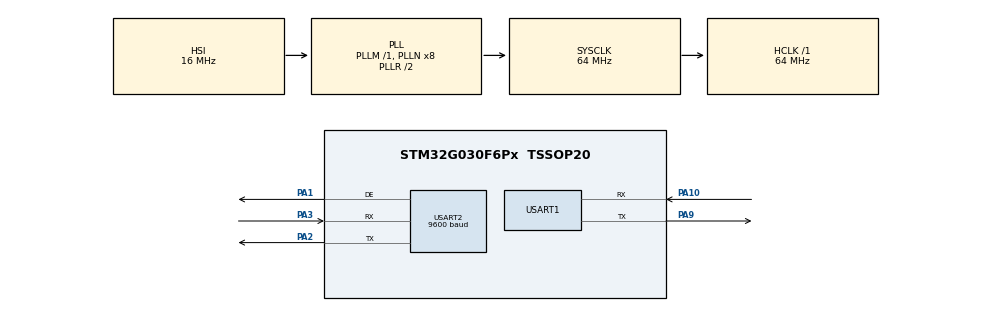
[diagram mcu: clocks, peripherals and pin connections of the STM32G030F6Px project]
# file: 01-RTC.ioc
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Mcu.Family=STM32G0
Mcu.Name=STM32G030F6Px
Mcu.Package=TSSOP20
NVIC.USART2_IRQn=true\:0\:0\:false\:false\:true\:true\:true\:true
PA1.Mode=Hardware Flow Control (RS485)
PA1.Signal=USART2_DE
PA10\ [PA12].Mode=Asynchronous
PA10\ [PA12].Signal=USART1_RX
PA13.Mode=Serial_Wire
PA13.Signal=SYS_SWDIO
PA14-BOOT0.Mode=Serial_Wire
PA14-BOOT0.Signal=SYS_SWCLK
PA14-BOOT0__PA15.StandardMode=true
PA2.Mode=Asynchronous
PA2.Signal=USART2_TX
PA3.Mode=Asynchronous
PA3.Signal=USART2_RX
PA9\ [PA11].Mode=Asynchronous
PA9\ [PA11].Signal=USART1_TX
PB0__PB1__PB2__PA8.StandardMode=true
PB3__PB4__PB5__PB6.StandardMode=true
PB7__PB8.StandardMode=true
PC14-OSC32_IN\ (PC14).Mode=LSE-External-Oscillator
PC14-OSC32_IN\ (PC14).Signal=RCC_OSC32_IN
PC14-OSC32_IN\ (PC14)__PB9.StandardMode=true
PC15-OSC32_OUT\ (PC15).Mode=LSE-External-Oscillator
PC15-OSC32_OUT\ (PC15).Signal=RCC_OSC32_OUT
ProjectManager.HeapSize=0x200
ProjectManager.StackSize=0x400
ProjectManager.TargetToolchain=STM32CubeIDE
RCC.ADCFreq_Value=64000000
RCC.AHBFreq_Value=64000000
RCC.CortexFreq_Value=64000000
RCC.EXTERNAL_CLOCK_VALUE=12288000
RCC.HCLKFreq_Value=64000000
RCC.HSE_VALUE=8000000
RCC.HSI_VALUE=16000000
RCC.RTCClockSelection=RCC_RTCCLKSOURCE_LSE
RCC.SYSCLKFreq_VALUE=64000000
RCC.SYSCLKSource=RCC_SYSCLKSOURCE_PLLCLK
RCC.VCOOutputFreq_Value=128000000
RTC.Year=23
USART1.VirtualMode-Asynchronous=VM_ASYNC
USART2.BaudRate=9600
USART2.VirtualMode-Asynchronous=VM_ASYNC
USART2.VirtualMode-Hardware\ Flow\ Control\ (RS485)=VM_ASYNC
VP_RTC_VS_RTC_Activate.Mode=RTC_Enabled
VP_RTC_VS_RTC_Calendar.Mode=RTC_Calendar
VP_SYS_VS_PINREMAP.Mode=PINREMAP
VP_SYS_VS_PINREMAP_10_12.Mode=PINREMAP_10_12
board=custom

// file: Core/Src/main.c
/* USER CODE BEGIN Header */
/**
  ******************************************************************************
  * @file           : main.c
  * @brief          : Main program body
  ******************************************************************************
  * @attention
  *
  * Copyright (c) 2026 STMicroelectronics.
  * All rights reserved.
  *
  * This software is licensed under terms that can be found in the LICENSE file
  * in the root directory of this software component.
  * If no LICENSE file comes with this software, it is provided AS-IS.
  *
  ******************************************************************************
  */
/* USER CODE END Header */
#include "main.h"
#include "rtc.h"
#include "usart.h"
#include "gpio.h"

/* USER CODE BEGIN Includes */
#include "modbus_slave.h"
/* USER CODE END Includes */

void SystemClock_Config(void);

int main(void)
{

  /* MCU Configuration--------------------------------------------------------*/

  /* Reset of all peripherals, Initializes the Flash interface and the Systick. */
  HAL_Init();

  /* Configure the system clock */
  SystemClock_Config();

  /* Initialize all configured peripherals */
  MX_GPIO_Init();
  MX_RTC_Init();
  MX_USART1_UART_Init();
  MX_USART2_UART_Init();
  /* USER CODE BEGIN 2 */
#ifndef LOOP_TEST_
  Modbus_Init();
#else
  // Optionally disable Modbus RX interrupt so it doesn't interfere
  __HAL_UART_DISABLE_IT(&huart2, UART_IT_RXNE);
#endif
  /* USER CODE END 2 */

  /* Infinite loop */
  while (1)
  {

    /* USER CODE BEGIN 3 */
#ifdef LOOP_TEST_
    RS485_LoopTest();
#else
    Modbus_Process();
#endif
  }
  /* USER CODE END 3 */
}

void SystemClock_Config(void)
{
  RCC_OscInitTypeDef RCC_OscInitStruct = {0};
  RCC_ClkInitTypeDef RCC_ClkInitStruct = {0};

  /** Configure the main internal regulator output voltage
  */
  HAL_PWREx_ControlVoltageScaling(PWR_REGULATOR_VOLTAGE_SCALE1);

  /** Configure LSE Drive Capability
  */
  HAL_PWR_EnableBkUpAccess();
  __HAL_RCC_LSEDRIVE_CONFIG(RCC_LSEDRIVE_LOW);

  /** Initializes the RCC Oscillators according to the specified parameters
  * in the RCC_OscInitTypeDef structure.
  */
  RCC_OscInitStruct.OscillatorType = RCC_OSCILLATORTYPE_HSI|RCC_OSCILLATORTYPE_LSE;
  RCC_OscInitStruct.LSEState = RCC_LSE_ON;
  RCC_OscInitStruct.HSIState = RCC_HSI_ON;
  RCC_OscInitStruct.HSIDiv = RCC_HSI_DIV1;
  RCC_OscInitStruct.HSICalibrationValue = RCC_HSICALIBRATION_DEFAULT;
  RCC_OscInitStruct.PLL.PLLState = RCC_PLL_ON;
  RCC_OscInitStruct.PLL.PLLSource = RCC_PLLSOURCE_HSI;
  RCC_OscInitStruct.PLL.PLLM = RCC_PLLM_DIV1;
  RCC_OscInitStruct.PLL.PLLN = 8;
  RCC_OscInitStruct.PLL.PLLP = RCC_PLLP_DIV2;
  RCC_OscInitStruct.PLL.PLLR = RCC_PLLR_DIV2;
  if (HAL_RCC_OscConfig(&RCC_OscInitStruct) != HAL_OK)
  {
    Error_Handler();
  }

  /** Initializes the CPU, AHB and APB buses clocks
  */
  RCC_ClkInitStruct.ClockType = RCC_CLOCKTYPE_HCLK|RCC_CLOCKTYPE_SYSCLK
                              |RCC_CLOCKTYPE_PCLK1;
  RCC_ClkInitStruct.SYSCLKSource = RCC_SYSCLKSOURCE_PLLCLK;
  RCC_ClkInitStruct.AHBCLKDivider = RCC_SYSCLK_DIV1;
  RCC_ClkInitStruct.APB1CLKDivider = RCC_HCLK_DIV1;

  if (HAL_RCC_ClockConfig(&RCC_ClkInitStruct, FLASH_LATENCY_2) != HAL_OK)
  {
    Error_Handler();
  }
}

void Error_Handler(void)
{
  __disable_irq();
  while (1)
  {
  }
}
